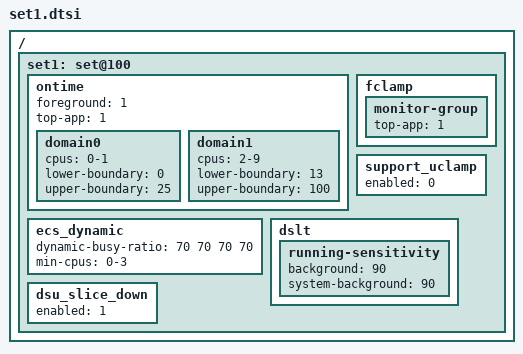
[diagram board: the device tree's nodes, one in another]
/ {
	/* power-scenario mode - default */
	set1: set@100 {
		/* Ontime Migration */
		ontime {
			foreground 	= <1>;
			top-app		= <1>;

			domain0 {
				cpus = "0-1";
				lower-boundary = <0>;
				upper-boundary = <25>;
			};
			domain1 {
				cpus = "2-9";
				lower-boundary = <13>;
				upper-boundary = <100>;
			};
		};

		ecs_dynamic {
			dynamic-busy-ratio = <70 70 70 70>;
			min-cpus = "0-3";
		};

		fclamp {
			monitor-group {
				top-app         = <1>;
			};
		};

		support_uclamp {
			enabled = <0>;
		};

		dslt {
			running-sensitivity {
				background = <90>;
				system-background = <90>;
			};
		};

		dsu_slice_down {
			enabled = <1>;
		};
	};
};
